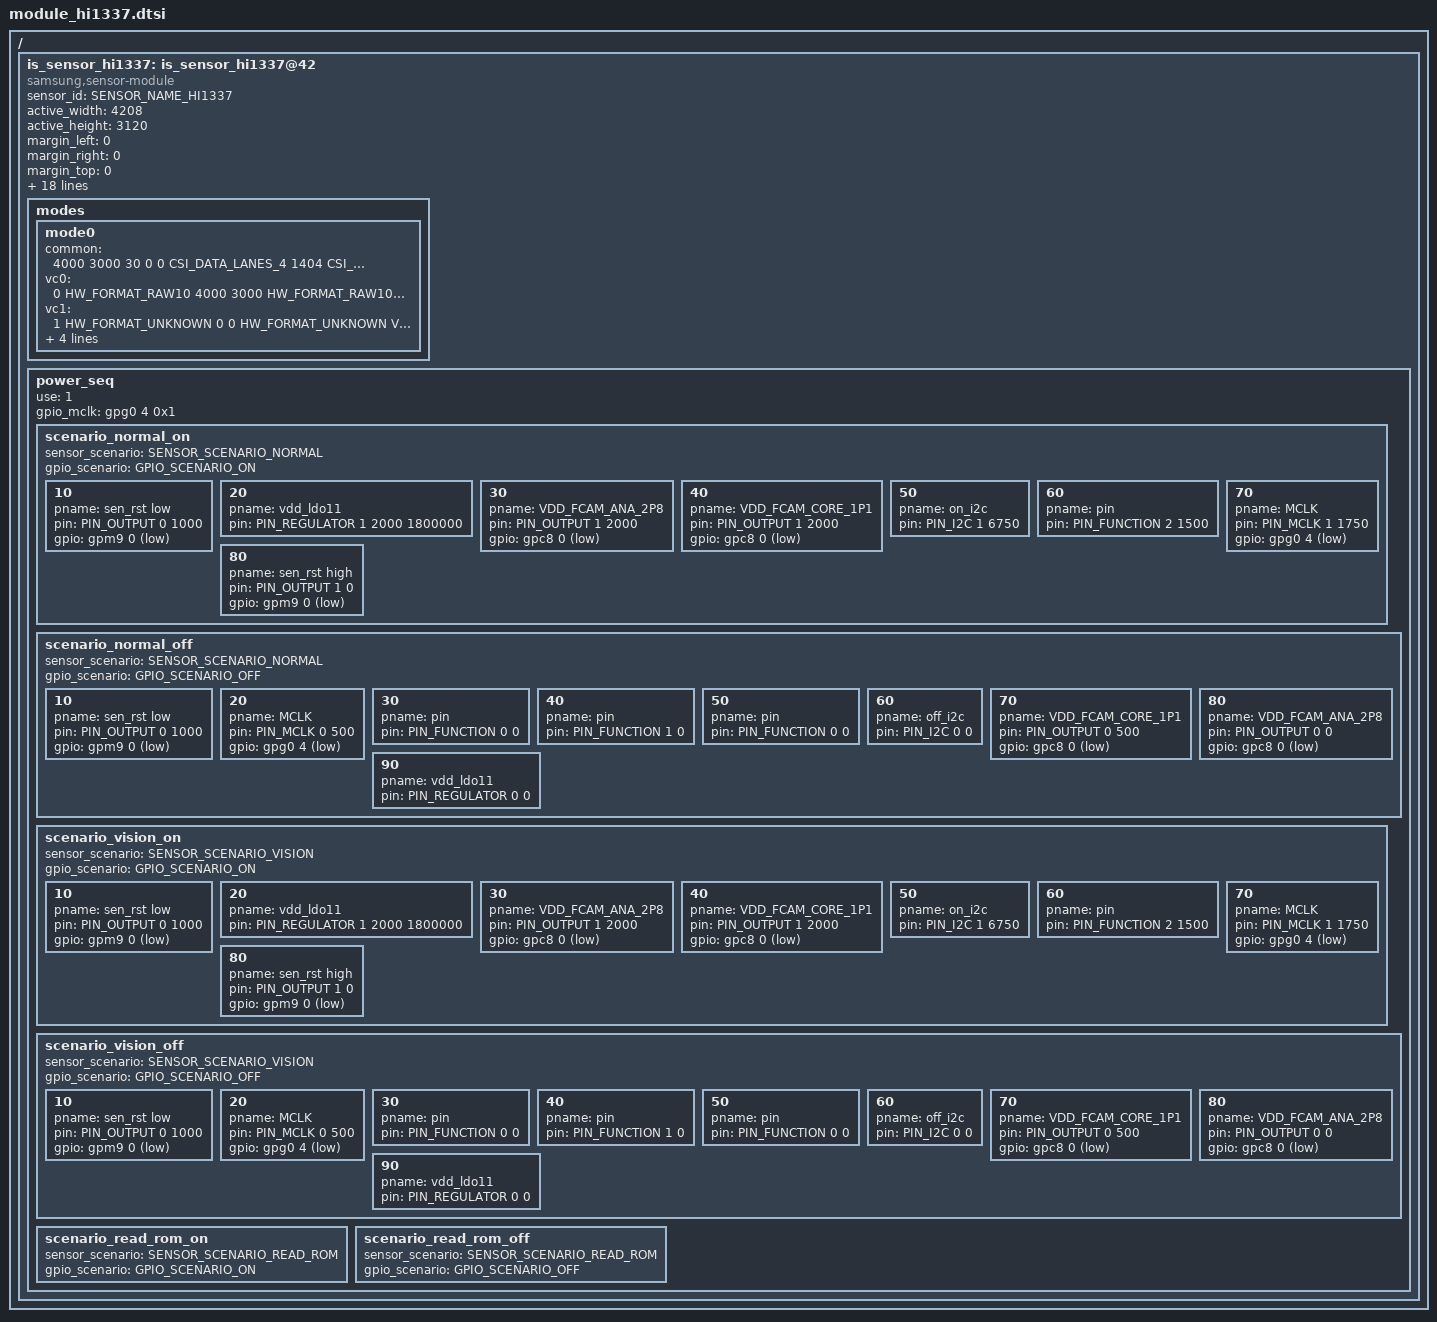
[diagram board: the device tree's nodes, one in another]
/*
 * SAMSUNG EXYNOSxxxx board camera device tree source
 *
 * Copyright (c) 2022 Samsung Electronics Co., Ltd.
 *		http://www.samsung.com
 *
 * This program is free software; you can redistribute it and/or modify
 * it under the terms of the GNU General Public License version 2 as
 * published by the Free Software Foundation.
 */

#include <dt-bindings/camera/exynos_is_dt.h>

/ {
	fragment@camera {
		target-path = "/";
		__overlay__ {
			is_sensor_hi1337: is_sensor_hi1337@42 {
				compatible = "samsung,sensor-module";

				/* common */
				sensor_id = <SENSOR_NAME_HI1337>;
				active_width = <4208>;
				active_height = <3120>;
				margin_left = <0>;
				margin_right = <0>;
				margin_top = <0>;
				margin_bottom = <0>;
				max_framerate = <120>;
				bitwidth = <10>;
				use_retention_mode = <SENSOR_RETENTION_INACTIVE>;
				sensor_maker = "HYNIX";
				sensor_name = "HI1337";
				setfile_name = "setfile_hi1337.bin";
				//pinning_setfile;
				//preload_setfile;

				status = "okay";

				/* board */
				pinctrl-names = "pin0", "pin1", "pin2", "release";
				pinctrl-0 = <>;
				pinctrl-1 = <&sensor_mclk2_out>;
				pinctrl-2 = <&sensor_mclk2_fn>;
				pinctrl-3 = <>;

				position = <1>; /* Rear:0. Front:1, Tele:2 */
				id = <1>; /* is_sensor id */
				mclk_ch = <2>;
				sensor_i2c_ch = <1>; /* SENSOR_CONTROL_I2C1 */

				/* vendor */
				rom_type = <2>; /* ROM_TYPE_EEPROM */
				rom_id = <1>;
				rom_cal_index = <0>;
#if 0
				vc_extra {
					/* ex) statX = <stat_type, sensor_mode, max_width, max_height, max_element> */
					/* VC_BUF_DATA_TYPE_SENSOR_STAT1 */
					stat0 = </*VC_STAT_TYPE_TAIL_FOR_3HDR_IMX_2_STAT0*/ 602    /*VC_SENSOR_MODE_3HDR_IMX_2*/ 602 4080 2 1>;
					/* VC_BUF_DATA_TYPE_GENERAL_STAT1 */
					stat1 = </* not available */>;
					/* VC_BUF_DATA_TYPE_SENSOR_STAT2 */
					stat2 = </*VC_STAT_TYPE_TAIL_FOR_3HDR_IMX_2_STAT1*/ 603    /*VC_SENSOR_MODE_3HDR_IMX_2*/ 602 4080 3 1>;
					/* VC_BUF_DATA_TYPE_GENERAL_STAT2 */
					stat3 = </* not available */>;
				};
#endif
				/*
				* [Mode Information]
				*
				* Reference File : Hi-1337_setting_v0.1.0.41_SEC11_20220830.xlsx
				*
				*  [ 0 ] 4000 x 3000(4:3)      @30,  MIPI lane: 4, MIPI data rate(Mbps/lane):  1495, Mclk(Mhz): 26
				*
				*/

				/* sensor modes */
				modes {
						/* common = <width, height, fps, settle, mode, lane, speed, interleave, lrte, pd_mode> */
						/* vcX = <map, hwformat, width, height, hwformat, type, width, height> */

						/* 0 : 4000x3000_30FPS */
						mode0 {
								common = <4000 3000 30 0 0 CSI_DATA_LANES_4 1404 CSI_MODE_VC_ONLY LRTE_DISABLE PD_NONE EX_NONE>;
								vc0 = </* in */ 0 HW_FORMAT_RAW10 4000 3000     /* out */ HW_FORMAT_RAW10 VC_NOTHING 4000 3000>;
								vc1 = </* in */ 1 HW_FORMAT_UNKNOWN 0 0         /* out */ HW_FORMAT_UNKNOWN VC_NOTHING 0 0>;
								vc2 = </* in */ 2 HW_FORMAT_UNKNOWN 0 0         /* out */ HW_FORMAT_UNKNOWN VC_NOTHING 0 0>;
								vc3 = </* in */ 3 HW_FORMAT_UNKNOWN 0 0         /* out */ HW_FORMAT_UNKNOWN VC_NOTHING 0 0>;
						};
				};

				power_seq {
					use = <1>;
					gpio_mclk = <&gpg0 4 0x1>;

					scenario_normal_on {
						sensor_scenario = <SENSOR_SCENARIO_NORMAL>;
						gpio_scenario = <GPIO_SCENARIO_ON>;

						/* A start node number should be over the 10 for reserved number 0~9. */
						/* pname = "name"; pin = <act value dealy voltage>; gpio = <gpx# # 0x1>; */
						10 { pname = "sen_rst low"; pin = <PIN_OUTPUT 0 1000>; gpio = <&gpm9 0 0x1>; };
						20 { pname = "vdd_ldo11"; pin = <PIN_REGULATOR 1 2000 1800000>; };
						30 { pname = "VDD_FCAM_ANA_2P8"; pin = <PIN_OUTPUT 1 2000>; gpio = <&gpc8 0 0x1>; };
						40 { pname = "VDD_FCAM_CORE_1P1"; pin = <PIN_OUTPUT 1 2000>; gpio = <&gpc8 0 0x1>; };
						50 { pname = "on_i2c"; pin = <PIN_I2C 1 6750>; };
						60 { pname = "pin"; pin = <PIN_FUNCTION 2 1500>; };
						70 { pname = "MCLK"; pin = <PIN_MCLK 1 1750>; gpio = <&gpg0 4 0x1>; };
						80 { pname = "sen_rst high"; pin = <PIN_OUTPUT 1 0>; gpio = <&gpm9 0 0x1>; };
					};

					scenario_normal_off {
						sensor_scenario = <SENSOR_SCENARIO_NORMAL>;
						gpio_scenario = <GPIO_SCENARIO_OFF>;

						/* A start node number should be over the 10 for reserved number 0~9. */
						/* pname = "name"; pin = <act value dealy voltage>; gpio = <gpx# # 0x1>; */
						10 { pname = "sen_rst low"; pin = <PIN_OUTPUT 0 1000>; gpio = <&gpm9 0 0x1>; };
						20 { pname = "MCLK"; pin = <PIN_MCLK 0 500>; gpio = <&gpg0 4 0x1>; };
						30 { pname = "pin"; pin = <PIN_FUNCTION 0 0>; };
						40 { pname = "pin"; pin = <PIN_FUNCTION 1 0>; };
						50 { pname = "pin"; pin = <PIN_FUNCTION 0 0>; };
						60 { pname = "off_i2c"; pin = <PIN_I2C 0 0>; };
						70 { pname = "VDD_FCAM_CORE_1P1"; pin = <PIN_OUTPUT 0 500>; gpio = <&gpc8 0 0x1>; };
						80 { pname = "VDD_FCAM_ANA_2P8"; pin = <PIN_OUTPUT 0 0>; gpio = <&gpc8 0 0x1>; };
						90 { pname = "vdd_ldo11"; pin = <PIN_REGULATOR 0 0>; };
					};
					scenario_vision_on {
						sensor_scenario = <SENSOR_SCENARIO_VISION>;
						gpio_scenario = <GPIO_SCENARIO_ON>;

						/* A start node number should be over the 10 for reserved number 0~9. */
						/* pname = "name"; pin = <act value dealy voltage>; gpio = <gpx# # 0x1>; */
						10 { pname = "sen_rst low"; pin = <PIN_OUTPUT 0 1000>; gpio = <&gpm9 0 0x1>; };
						20 { pname = "vdd_ldo11"; pin = <PIN_REGULATOR 1 2000 1800000>; };
						30 { pname = "VDD_FCAM_ANA_2P8"; pin = <PIN_OUTPUT 1 2000>; gpio = <&gpc8 0 0x1>; };
						40 { pname = "VDD_FCAM_CORE_1P1"; pin = <PIN_OUTPUT 1 2000>; gpio = <&gpc8 0 0x1>; };
						50 { pname = "on_i2c"; pin = <PIN_I2C 1 6750>; };
						60 { pname = "pin"; pin = <PIN_FUNCTION 2 1500>; };
						70 { pname = "MCLK"; pin = <PIN_MCLK 1 1750>; gpio = <&gpg0 4 0x1>; };
						80 { pname = "sen_rst high"; pin = <PIN_OUTPUT 1 0>; gpio = <&gpm9 0 0x1>; };
					};

					scenario_vision_off {
						sensor_scenario = <SENSOR_SCENARIO_VISION>;
						gpio_scenario = <GPIO_SCENARIO_OFF>;

						/* A start node number should be over the 10 for reserved number 0~9. */
						/* pname = "name"; pin = <act value dealy voltage>; gpio = <gpx# # 0x1>; */
						10 { pname = "sen_rst low"; pin = <PIN_OUTPUT 0 1000>; gpio = <&gpm9 0 0x1>; };
						20 { pname = "MCLK"; pin = <PIN_MCLK 0 500>; gpio = <&gpg0 4 0x1>; };
						30 { pname = "pin"; pin = <PIN_FUNCTION 0 0>; };
						40 { pname = "pin"; pin = <PIN_FUNCTION 1 0>; };
						50 { pname = "pin"; pin = <PIN_FUNCTION 0 0>; };
						60 { pname = "off_i2c"; pin = <PIN_I2C 0 0>; };
						70 { pname = "VDD_FCAM_CORE_1P1"; pin = <PIN_OUTPUT 0 500>; gpio = <&gpc8 0 0x1>; };
						80 { pname = "VDD_FCAM_ANA_2P8"; pin = <PIN_OUTPUT 0 0>; gpio = <&gpc8 0 0x1>; };
						90 { pname = "vdd_ldo11"; pin = <PIN_REGULATOR 0 0>; };
					};

					scenario_read_rom_on {
						sensor_scenario = <SENSOR_SCENARIO_READ_ROM>;
						gpio_scenario = <GPIO_SCENARIO_ON>;

						/* A start node number should be over the 10 for reserved number 0~9. */
						/* pname = "name"; pin = <act value dealy voltage>; gpio = <gpx# # 0x1>; */
						//10 { pname = "VDDIO_1.8V_CAM"; pin = <PIN_REGULATOR 1 6500>; };
						//20 { pname = "on_i2c"; pin = <PIN_I2C 1 0>; };
					};

					scenario_read_rom_off {
						sensor_scenario = <SENSOR_SCENARIO_READ_ROM>;
						gpio_scenario = <GPIO_SCENARIO_OFF>;

						/* A start node number should be over the 10 for reserved number 0~9. */
						/* pname = "name"; pin = <act value dealy voltage>; gpio = <gpx# # 0x1>; */
						//10 { pname = "off_i2c"; pin = <PIN_I2C 0 0>; };
						//20 { pname = "VDDIO_1.8V_CAM"; pin = <PIN_REGULATOR 0 20000>; };
					};
				};
			};
		}; /* end of __overlay__ */
	}; /* end of fragment */
}; /* end of root */
